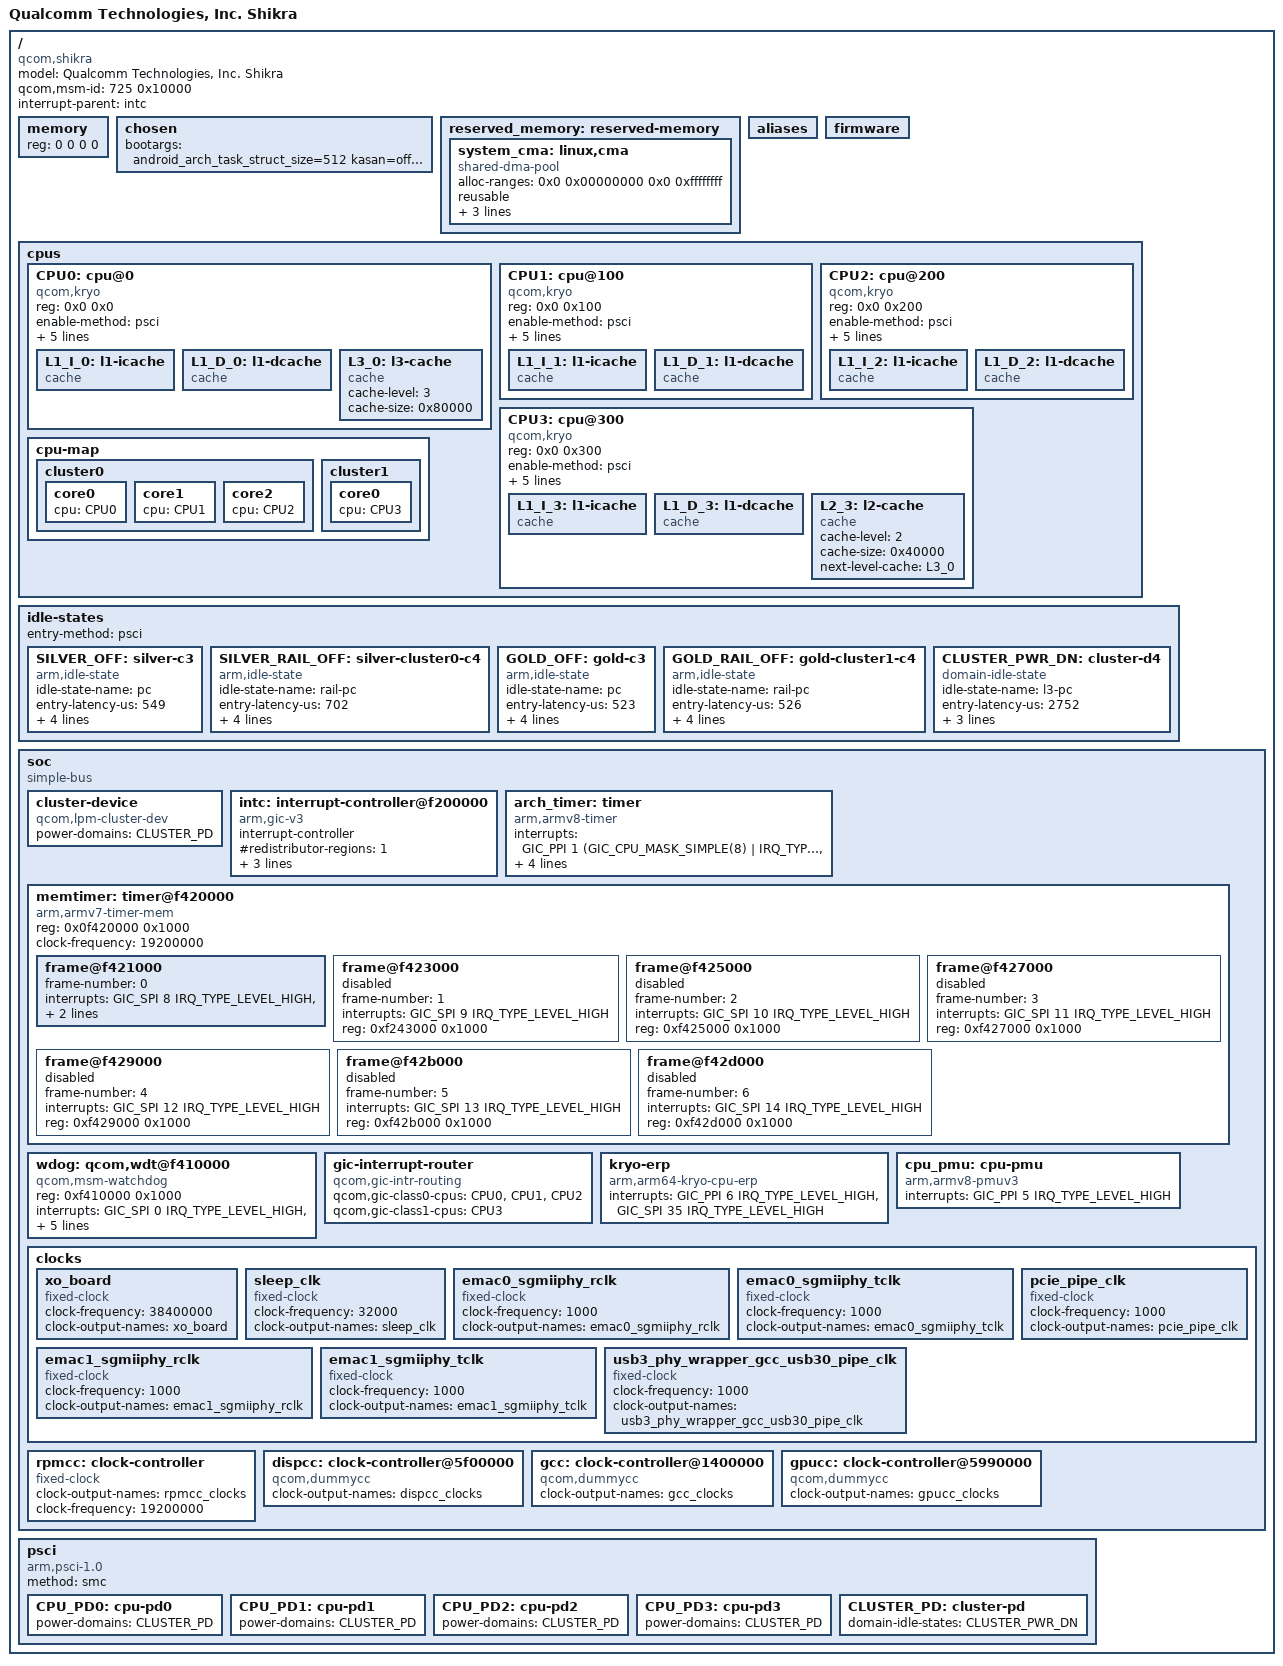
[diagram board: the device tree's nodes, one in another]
// SPDX-License-Identifier: BSD-3-Clause
/*
 * Copyright (c) Qualcomm Technologies, Inc. and/or its subsidiaries.
 */

#include <dt-bindings/clock/qcom,rpmcc.h>
#include <dt-bindings/clock/qcom,shikra-dispcc.h>
#include <dt-bindings/clock/qcom,shikra-gcc.h>
#include <dt-bindings/clock/qcom,shikra-gpucc.h>
#include <dt-bindings/interrupt-controller/arm-gic.h>
#include <dt-bindings/regulator/qcom,rpmh-regulator-levels.h>

/ {
	model = "Qualcomm Technologies, Inc. Shikra";
	compatible = "qcom,shikra";
	qcom,msm-id = <725 0x10000 >;//TODO - update actual msm-id for shikra
	interrupt-parent = <&intc>;
	#address-cells = <2>;
	#size-cells = <2>;
	memory { device_type = "memory"; reg = <0 0 0 0>; };

	chosen: chosen {
		bootargs = "android_arch_task_struct_size=512 kasan=off irqaffinity=0-1 cpufreq.default_governor=performance printk.console_no_auto_verbose=1 rcupdate.rcu_expedited=1 rcu_nocbs=0-4 nokaslr kpti=0 log_buf_len=256K swiotlb=0 loop.max_part=7 loglevel=8";
	};

	reserved_memory: reserved-memory { };

	aliases { };

	firmware: firmware {};

	cpus {
		#address-cells = <2>;
		#size-cells = <0>;

		CPU0: cpu@0 {
			device_type = "cpu";
			compatible = "qcom,kryo";
			reg = <0x0 0x0>;
			enable-method = "psci";
			cpu-idle-states = <&SILVER_OFF &SILVER_RAIL_OFF>;
			power-domains = <&CPU_PD0>;
			power-domain-names = "psci";
			d-cache-size = <0x8000>;
			i-cache-size = <0x8000>;
			next-level-cache = <&L3_0>;

			L1_I_0: l1-icache {
				compatible = "cache";
			};

			L1_D_0: l1-dcache {
				compatible = "cache";
			};

			L3_0: l3-cache {
				compatible = "cache";
				cache-level = <3>;
				cache-size = <0x80000>;
			};
		};

		CPU1: cpu@100 {
			device_type = "cpu";
			compatible = "qcom,kryo";
			reg = <0x0 0x100>;
			enable-method = "psci";
			cpu-idle-states = <&SILVER_OFF &SILVER_RAIL_OFF>;
			power-domains = <&CPU_PD1>;
			power-domain-names = "psci";
			d-cache-size = <0x8000>;
			i-cache-size = <0x8000>;
			next-level-cache = <&L3_0>;

			L1_I_1: l1-icache {
				compatible = "cache";
			};

			L1_D_1: l1-dcache {
				compatible = "cache";
			};
		};

		CPU2: cpu@200 {
			device_type = "cpu";
			compatible = "qcom,kryo";
			reg = <0x0 0x200>;
			enable-method = "psci";
			cpu-idle-states = <&SILVER_OFF &SILVER_RAIL_OFF>;
			power-domains = <&CPU_PD2>;
			power-domain-names = "psci";
			d-cache-size = <0x8000>;
			i-cache-size = <0x8000>;
			next-level-cache = <&L3_0>;

			L1_I_2: l1-icache {
				compatible = "cache";
			};

			L1_D_2: l1-dcache {
				compatible = "cache";
			};
		};

		CPU3: cpu@300 {
			device_type = "cpu";
			compatible = "qcom,kryo";
			reg = <0x0 0x300>;
			enable-method = "psci";
			cpu-idle-states = <&GOLD_OFF &GOLD_RAIL_OFF>;
			power-domains = <&CPU_PD3>;
			power-domain-names = "psci";
			d-cache-size = <0x8000>;
			i-cache-size = <0x8000>;
			next-level-cache = <&L2_3>;

			L1_I_3: l1-icache {
				compatible = "cache";
			};

			L1_D_3: l1-dcache {
				compatible = "cache";
			};

			L2_3: l2-cache {
				compatible = "cache";
				cache-level = <2>;
				cache-size = <0x40000>;
				next-level-cache = <&L3_0>;
			};
		};

		cpu-map {
			cluster0 {
				core0 {
					cpu = <&CPU0>;
				};

				core1 {
					cpu = <&CPU1>;
				};

				core2 {
					cpu = <&CPU2>;
				};
			};

			cluster1 {
				core0 {
					cpu = <&CPU3>;
				};
			};
		};
	};

	idle-states {
		entry-method = "psci";

		SILVER_OFF: silver-c3 {  /* C3 */
			compatible = "arm,idle-state";
			idle-state-name = "pc";
			entry-latency-us = <549>;
			exit-latency-us = <901>;
			min-residency-us = <1774>;
			arm,psci-suspend-param = <0x40000003>;
			local-timer-stop;
		};

		SILVER_RAIL_OFF: silver-cluster0-c4 { /* C4 */
			compatible = "arm,idle-state";
			idle-state-name = "rail-pc";
			entry-latency-us = <702>;
			exit-latency-us = <915>;
			min-residency-us = <4001>;
			arm,psci-suspend-param = <0x40000004>;
			local-timer-stop;
		};

		GOLD_OFF: gold-c3 {  /* C3 */
			compatible = "arm,idle-state";
			idle-state-name = "pc";
			entry-latency-us = <523>;
			exit-latency-us = <1244>;
			min-residency-us = <2207>;
			arm,psci-suspend-param = <0x40000003>;
			local-timer-stop;
		};

		GOLD_RAIL_OFF: gold-cluster1-c4 { /* C4 */
			compatible = "arm,idle-state";
			idle-state-name = "rail-pc";
			entry-latency-us = <526>;
			exit-latency-us = <1854>;
			min-residency-us = <5555>;
			arm,psci-suspend-param = <0x40000004>;
			local-timer-stop;
		};

		CLUSTER_PWR_DN: cluster-d4 { /* D4 */
			compatible = "domain-idle-state";
			idle-state-name = "l3-pc";
			entry-latency-us = <2752>;
			exit-latency-us = <3038>;
			min-residency-us = <6118>;
			arm,psci-suspend-param = <0x41000044>;
		};
	};

	soc: soc { };

	psci {
		compatible = "arm,psci-1.0";
		method = "smc";

		CPU_PD0: cpu-pd0 {
			#power-domain-cells = <0>;
			power-domains = <&CLUSTER_PD>;
		};

		CPU_PD1: cpu-pd1 {
			#power-domain-cells = <0>;
			power-domains = <&CLUSTER_PD>;
		};

		CPU_PD2: cpu-pd2 {
			#power-domain-cells = <0>;
			power-domains = <&CLUSTER_PD>;
		};

		CPU_PD3: cpu-pd3 {
			#power-domain-cells = <0>;
			power-domains = <&CLUSTER_PD>;
		};

		CLUSTER_PD: cluster-pd {
			#power-domain-cells = <0>;
			domain-idle-states = <&CLUSTER_PWR_DN>;
		};
	};
};

&soc {
	#address-cells = <1>;
	#size-cells = <1>;
	ranges = <0 0 0 0xffffffff>;
	compatible = "simple-bus";

	cluster-device {
		compatible = "qcom,lpm-cluster-dev";
		power-domains = <&CLUSTER_PD>;
	};

	intc: interrupt-controller@f200000 {
		compatible = "arm,gic-v3";
		#interrupt-cells = <3>;
		interrupt-controller;
		#redistributor-regions = <1>;
		redistributor-stride = <0x0 0x20000>;
		reg = <0xf200000 0x10000>,	/* GICD */
		      <0xf240000 0x80000>;	/* GICR * 4 */
		interrupts = <GIC_PPI 8 IRQ_TYPE_LEVEL_HIGH>;
	};

	arch_timer: timer {
		compatible = "arm,armv8-timer";
		interrupts = <GIC_PPI 1 (GIC_CPU_MASK_SIMPLE(8) | IRQ_TYPE_LEVEL_LOW)>,
			     <GIC_PPI 2 (GIC_CPU_MASK_SIMPLE(8) | IRQ_TYPE_LEVEL_LOW)>,
			     <GIC_PPI 3 (GIC_CPU_MASK_SIMPLE(8) | IRQ_TYPE_LEVEL_LOW)>,
			     <GIC_PPI 0 (GIC_CPU_MASK_SIMPLE(8) | IRQ_TYPE_LEVEL_LOW)>;
		clock-frequency = <19200000>;
	};

	memtimer: timer@f420000 {
		#address-cells = <1>;
		#size-cells = <1>;
		ranges;
		compatible = "arm,armv7-timer-mem";
		reg = <0x0f420000 0x1000>;
		clock-frequency = <19200000>;

		frame@f421000 {
			frame-number = <0>;
			interrupts = <GIC_SPI 8 IRQ_TYPE_LEVEL_HIGH>,
				     <GIC_SPI 6 IRQ_TYPE_LEVEL_HIGH>;
			reg = <0x0f421000 0x1000>,
			      <0x0f422000 0x1000>;
		};

		frame@f423000 {
			frame-number = <1>;
			interrupts = <GIC_SPI 9 IRQ_TYPE_LEVEL_HIGH>;
			reg = <0xf243000 0x1000>;
			status = "disabled";
		};

		frame@f425000 {
			frame-number = <2>;
			interrupts = <GIC_SPI 10 IRQ_TYPE_LEVEL_HIGH>;
			reg = <0xf425000 0x1000>;
			status = "disabled";
		};

		frame@f427000 {
			frame-number = <3>;
			interrupts = <GIC_SPI 11 IRQ_TYPE_LEVEL_HIGH>;
			reg = <0xf427000 0x1000>;
			status = "disabled";
		};

		frame@f429000 {
			frame-number = <4>;
			interrupts = <GIC_SPI 12 IRQ_TYPE_LEVEL_HIGH>;
			reg = <0xf429000 0x1000>;
			status = "disabled";
		};

		frame@f42b000 {
			frame-number = <5>;
			interrupts = <GIC_SPI 13 IRQ_TYPE_LEVEL_HIGH>;
			reg = <0xf42b000 0x1000>;
			status = "disabled";
		};

		frame@f42d000 {
			frame-number = <6>;
			interrupts = <GIC_SPI 14 IRQ_TYPE_LEVEL_HIGH>;
			reg = <0xf42d000 0x1000>;
			status = "disabled";
		};
	};

	wdog: qcom,wdt@f410000 {
		compatible = "qcom,msm-watchdog";
		reg = <0xf410000 0x1000>;
		reg-names = "wdt-base";
		interrupts = <GIC_SPI 0 IRQ_TYPE_LEVEL_HIGH>,
			     <GIC_SPI 1 IRQ_TYPE_LEVEL_HIGH>;
		qcom,bark-time = <11000>;
		qcom,pet-time = <9360>;
		qcom,ipi-ping;
		qcom,wakeup-enable;
		status = "ok";
	};

	gic-interrupt-router {
		compatible = "qcom,gic-intr-routing";
		/* keep a few m cores in class0 only to avoid wakeup of l cores */
		qcom,gic-class0-cpus = <&CPU0 &CPU1 &CPU2>;
		/* keep other cores in class1 */
		qcom,gic-class1-cpus = <&CPU3>;
	};

	kryo-erp {
		compatible = "arm,arm64-kryo-cpu-erp";
		interrupts = <GIC_PPI 6 IRQ_TYPE_LEVEL_HIGH>,
			     <GIC_SPI 35 IRQ_TYPE_LEVEL_HIGH>;
		interrupt-names = "l1-l2-faultirq","l3-scu-faultirq";
	};

	cpu_pmu: cpu-pmu {
		compatible = "arm,armv8-pmuv3";
		interrupts = <GIC_PPI 5 IRQ_TYPE_LEVEL_HIGH>;
	};

	clocks {
		xo_board: xo_board {
			compatible = "fixed-clock";
			clock-frequency = <38400000>;
			clock-output-names = "xo_board";
			#clock-cells = <0>;
		};

		sleep_clk: sleep_clk {
			compatible = "fixed-clock";
			clock-frequency = <32000>;
			clock-output-names = "sleep_clk";
			#clock-cells = <0>;
		};

		emac0_sgmiiphy_rclk: emac0_sgmiiphy_rclk {
			compatible = "fixed-clock";
			clock-frequency = <1000>;
			clock-output-names = "emac0_sgmiiphy_rclk";
			#clock-cells = <0>;
		};

		emac0_sgmiiphy_tclk: emac0_sgmiiphy_tclk {
			compatible = "fixed-clock";
			clock-frequency = <1000>;
			clock-output-names = "emac0_sgmiiphy_tclk";
			#clock-cells = <0>;
		};

		emac1_sgmiiphy_rclk: emac1_sgmiiphy_rclk {
			compatible = "fixed-clock";
			clock-frequency = <1000>;
			clock-output-names = "emac1_sgmiiphy_rclk";
			#clock-cells = <0>;
		};

		emac1_sgmiiphy_tclk: emac1_sgmiiphy_tclk {
			compatible = "fixed-clock";
			clock-frequency = <1000>;
			clock-output-names = "emac1_sgmiiphy_tclk";
			#clock-cells = <0>;
		};

		pcie_pipe_clk: pcie_pipe_clk {
			compatible = "fixed-clock";
			clock-frequency = <1000>;
			clock-output-names = "pcie_pipe_clk";
			#clock-cells = <0>;
		};

		usb3_phy_wrapper_gcc_usb30_pipe_clk: usb3_phy_wrapper_gcc_usb30_pipe_clk {
			compatible = "fixed-clock";
			clock-frequency = <1000>;
			clock-output-names = "usb3_phy_wrapper_gcc_usb30_pipe_clk";
			#clock-cells = <0>;
		};
	};

	rpmcc: clock-controller {
		compatible = "fixed-clock";
		clock-output-names = "rpmcc_clocks";
		clock-frequency = <19200000>;
		#clock-cells = <1>;
	};

	dispcc: clock-controller@5f00000 {
		compatible = "qcom,dummycc";
		clock-output-names = "dispcc_clocks";
		#clock-cells = <1>;
		#reset-cells = <1>;
		#power-domain-cells = <1>;
	};

	gcc: clock-controller@1400000 {
		compatible = "qcom,dummycc";
		clock-output-names = "gcc_clocks";
		#clock-cells = <1>;
		#reset-cells = <1>;
		#power-domain-cells = <1>;
	};

	gpucc: clock-controller@5990000 {
		compatible = "qcom,dummycc";
		clock-output-names = "gpucc_clocks";
		#clock-cells = <1>;
		#reset-cells = <1>;
		#power-domain-cells = <1>;
	};
};

#include "shikra-pinctrl.dtsi"
#include "shikra-reserved-memory.dtsi"
#include "shikra-stub-regulators.dtsi"
#include "msm-arm-smmu-shikra.dtsi"
#include "shikra-dma-heaps.dtsi"

&reserved_memory {
	#address-cells = <2>;
	#size-cells = <2>;
	ranges;
	/* global autoconfigured region for contiguous allocations */
    system_cma: linux,cma {
		compatible = "shared-dma-pool";
		alloc-ranges = <0x0 0x00000000 0x0 0xffffffff>;
		reusable;
		alignment = <0x0 0x400000>;
		size = <0x0 0x1000000>;
		linux,cma-default;
	};
};
